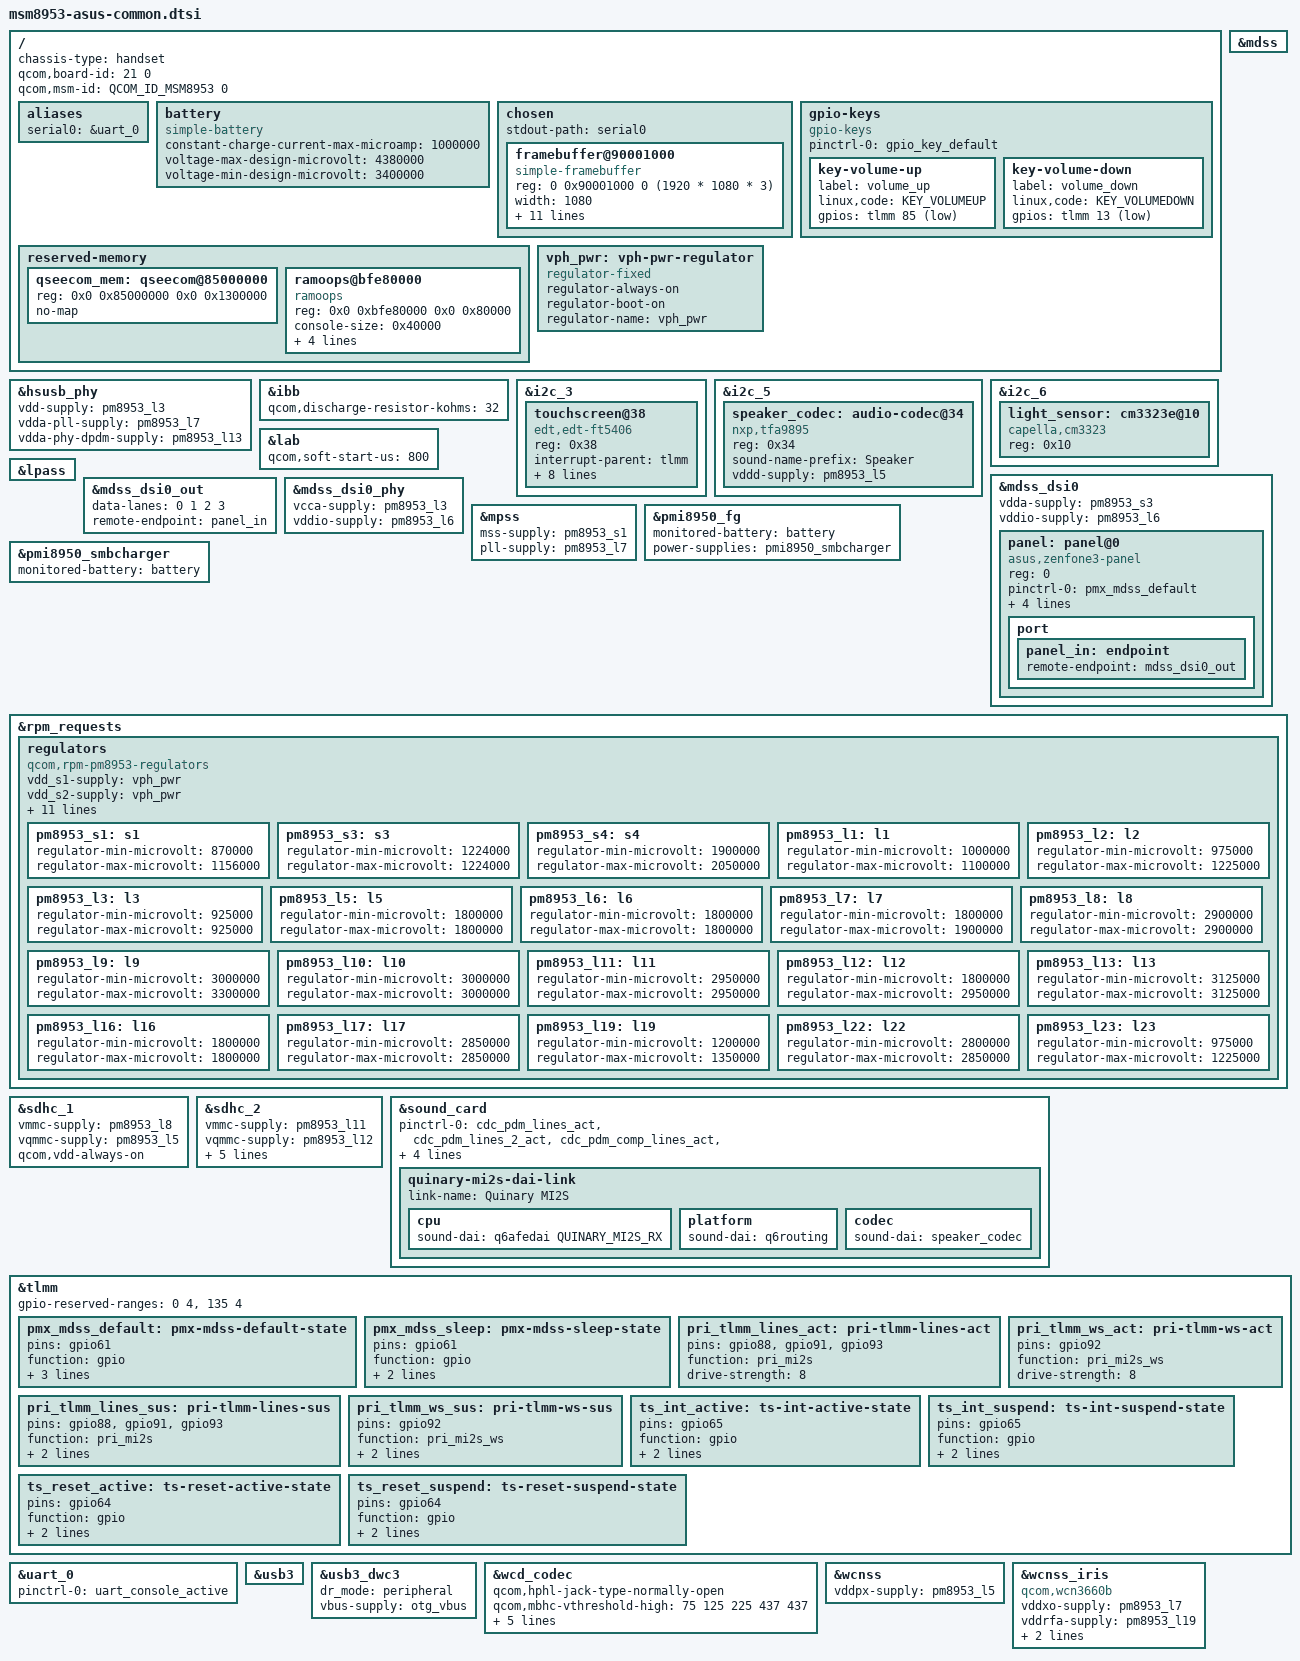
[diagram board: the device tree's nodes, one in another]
// SPDX-License-Identifier: BSD-3-Clause
/*
 * Copyright (c) 2024, Antony Kurniawan S. <postmarketos@smankusors.com>
 */
/dts-v1/;

#include <dt-bindings/arm/qcom,ids.h>
#include "msm8953.dtsi"
#include "pm8953.dtsi"
#include "pmi8950.dtsi"

/ {
	chassis-type = "handset";
	qcom,board-id = <21 0>;
	qcom,msm-id = <QCOM_ID_MSM8953 0>;

	aliases {
		serial0 = &uart_0;
	};

	battery: battery {
		compatible = "simple-battery";

		constant-charge-current-max-microamp = <1000000>;
		voltage-max-design-microvolt = <4380000>;
		voltage-min-design-microvolt = <3400000>;
	};

	chosen {
		#address-cells = <2>;
		#size-cells = <2>;
		ranges;
		stdout-path = "serial0";

		framebuffer@90001000 {
			compatible = "simple-framebuffer";
			reg = <0 0x90001000 0 (1920 * 1080 * 3)>;

			width = <1080>;
			height = <1920>;
			stride = <(1080 * 3)>;
			format = "r8g8b8";

			power-domains = <&gcc MDSS_GDSC>;

			clocks = <&gcc GCC_MDSS_AHB_CLK>,
				 <&gcc GCC_MDSS_AXI_CLK>,
				 <&gcc GCC_MDSS_VSYNC_CLK>,
				 <&gcc GCC_MDSS_MDP_CLK>,
				 <&gcc GCC_MDSS_BYTE0_CLK>,
				 <&gcc GCC_MDSS_PCLK0_CLK>,
				 <&gcc GCC_MDSS_ESC0_CLK>;
		};
	};

	gpio-keys {
		compatible = "gpio-keys";

		pinctrl-0 = <&gpio_key_default>;
		pinctrl-names = "default";

		key-volume-up {
			label = "volume_up";
			linux,code = <KEY_VOLUMEUP>;
			gpios = <&tlmm 85 GPIO_ACTIVE_LOW>;
		};

		key-volume-down {
			label = "volume_down";
			linux,code = <KEY_VOLUMEDOWN>;
			gpios = <&tlmm 13 GPIO_ACTIVE_LOW>;
		};
	};

	reserved-memory {
		/delete-node/ qseecom@85b00000;
		qseecom_mem: qseecom@85000000 {
			reg = <0x0 0x85000000 0x0 0x1300000>;
			no-map;
		};

		ramoops@bfe80000 {
			compatible = "ramoops";
			reg = <0x0 0xbfe80000 0x0 0x80000>;
			console-size = <0x40000>;
			ftrace-size = <0x0>;
			record-size = <0x2000>;
			pmsg-size = <0x0>;
			dump-size = <0x3e000>;
		};
	};

	vph_pwr: vph-pwr-regulator {
		compatible = "regulator-fixed";
		regulator-always-on;
		regulator-boot-on;
		regulator-name = "vph_pwr";
	};
};

&hsusb_phy {
	vdd-supply = <&pm8953_l3>;
	vdda-pll-supply = <&pm8953_l7>;
	vdda-phy-dpdm-supply = <&pm8953_l13>;

	status = "okay";
};

&ibb {
	qcom,discharge-resistor-kohms = <32>;
};

&i2c_3 {
	status = "okay";

	touchscreen@38 {
		compatible = "edt,edt-ft5406";
		reg = <0x38>;

		interrupt-parent = <&tlmm>;
		interrupts = <65 IRQ_TYPE_EDGE_FALLING>;

		pinctrl-0 = <&ts_reset_active &ts_int_active>;
		pinctrl-1 = <&ts_reset_suspend &ts_int_suspend>;
		pinctrl-names = "default", "sleep";

		reset-gpios = <&tlmm 64 GPIO_ACTIVE_LOW>;

		iovcc-supply = <&pm8953_l6>;
		vcc-supply = <&pm8953_l10>;

		touchscreen-size-x = <1080>;
		touchscreen-size-y = <1920>;
	};
};

&i2c_5 {
	status = "okay";

	speaker_codec: audio-codec@34 {
		compatible = "nxp,tfa9895";
		reg = <0x34>;
		sound-name-prefix = "Speaker";
		vddd-supply = <&pm8953_l5>;
		#sound-dai-cells = <0>;
	};
};

&i2c_6 {
	status = "okay";

	light_sensor: cm3323e@10 {
		compatible = "capella,cm3323";
		reg = <0x10>;
	};
};

&lab {
	qcom,soft-start-us = <800>;
};

&lpass {
	status = "okay";
};

&mdss {
	status = "okay";
};

&mdss_dsi0 {
	vdda-supply = <&pm8953_s3>;
	vddio-supply = <&pm8953_l6>;
	status = "okay";

	panel: panel@0 {
		compatible = "asus,zenfone3-panel";
		reg = <0>;

		pinctrl-0 = <&pmx_mdss_default>;
		pinctrl-1 = <&pmx_mdss_sleep>;
		pinctrl-names = "default", "sleep";

		reset-gpios = <&tlmm 61 GPIO_ACTIVE_LOW>;

		vsp-supply = <&lab>;
		vsn-supply = <&ibb>;

		port {
			panel_in: endpoint {
				remote-endpoint = <&mdss_dsi0_out>;
			};
		};
	};
};

&mdss_dsi0_out {
	data-lanes = <0 1 2 3>;
	remote-endpoint = <&panel_in>;
};

&mdss_dsi0_phy {
	vcca-supply = <&pm8953_l3>;
	vddio-supply = <&pm8953_l6>;

	status = "okay";
};

&mpss {
	mss-supply = <&pm8953_s1>;
	pll-supply = <&pm8953_l7>;

	status = "okay";
};

&pmi8950_fg {
	monitored-battery = <&battery>;
	power-supplies = <&pmi8950_smbcharger>;
};

&pmi8950_smbcharger {
	monitored-battery = <&battery>;
	status = "okay";
};

&rpm_requests {
	regulators {
		compatible = "qcom,rpm-pm8953-regulators";
		vdd_s1-supply = <&vph_pwr>;
		vdd_s2-supply = <&vph_pwr>;
		vdd_s3-supply = <&vph_pwr>;
		vdd_s4-supply = <&vph_pwr>;
		vdd_s5-supply = <&vph_pwr>;
		vdd_s6-supply = <&vph_pwr>;
		vdd_s7-supply = <&vph_pwr>;
		vdd_l1-supply = <&pm8953_s3>;
		vdd_l2_l3-supply = <&pm8953_s3>;
		vdd_l4_l5_l6_l7_l16_l19-supply = <&pm8953_s4>;
		vdd_l8_l11_l12_l13_l14_l15-supply = <&vph_pwr>;
		vdd_l9_l10_l17_l18_l22-supply = <&vph_pwr>;
		vdd_l23-supply = <&pm8953_s3>;

		pm8953_s1: s1 {
			regulator-min-microvolt = <870000>;
			regulator-max-microvolt = <1156000>;
		};

		pm8953_s3: s3 {
			regulator-min-microvolt = <1224000>;
			regulator-max-microvolt = <1224000>;
		};

		pm8953_s4: s4 {
			regulator-min-microvolt = <1900000>;
			regulator-max-microvolt = <2050000>;
		};

		pm8953_l1: l1 {
			regulator-min-microvolt = <1000000>;
			regulator-max-microvolt = <1100000>;
		};

		pm8953_l2: l2 {
			regulator-min-microvolt = <975000>;
			regulator-max-microvolt = <1225000>;
		};

		pm8953_l3: l3 {
			regulator-min-microvolt = <925000>;
			regulator-max-microvolt = <925000>;
		};

		pm8953_l5: l5 {
			regulator-min-microvolt = <1800000>;
			regulator-max-microvolt = <1800000>;
		};

		pm8953_l6: l6 {
			regulator-min-microvolt = <1800000>;
			regulator-max-microvolt = <1800000>;
		};

		pm8953_l7: l7 {
			regulator-min-microvolt = <1800000>;
			regulator-max-microvolt = <1900000>;
		};

		pm8953_l8: l8 {
			regulator-min-microvolt = <2900000>;
			regulator-max-microvolt = <2900000>;
		};

		pm8953_l9: l9 {
			regulator-min-microvolt = <3000000>;
			regulator-max-microvolt = <3300000>;
		};

		pm8953_l10: l10 {
			regulator-min-microvolt = <3000000>;
			regulator-max-microvolt = <3000000>;
		};

		pm8953_l11: l11 {
			regulator-min-microvolt = <2950000>;
			regulator-max-microvolt = <2950000>;
		};

		pm8953_l12: l12 {
			regulator-min-microvolt = <1800000>;
			regulator-max-microvolt = <2950000>;
		};

		pm8953_l13: l13 {
			regulator-min-microvolt = <3125000>;
			regulator-max-microvolt = <3125000>;
		};

		pm8953_l16: l16 {
			regulator-min-microvolt = <1800000>;
			regulator-max-microvolt = <1800000>;
		};

		pm8953_l17: l17 {
			regulator-min-microvolt = <2850000>;
			regulator-max-microvolt = <2850000>;
		};

		pm8953_l19: l19 {
			regulator-min-microvolt = <1200000>;
			regulator-max-microvolt = <1350000>;
		};

		pm8953_l22: l22 {
			regulator-min-microvolt = <2800000>;
			regulator-max-microvolt = <2850000>;
		};

		pm8953_l23: l23 {
			regulator-min-microvolt = <975000>;
			regulator-max-microvolt = <1225000>;
		};
	};
};

&sdhc_1 {
	vmmc-supply = <&pm8953_l8>;
	vqmmc-supply = <&pm8953_l5>;
	qcom,vdd-always-on;

	status = "okay";
};

&sdhc_2 {
	vmmc-supply = <&pm8953_l11>;
	vqmmc-supply = <&pm8953_l12>;

	cd-gpios = <&tlmm 133 GPIO_ACTIVE_LOW>;

	pinctrl-0 = <&sdc2_clk_on &sdc2_cmd_on &sdc2_data_on &sdc2_cd_on>;
	pinctrl-1 = <&sdc2_clk_off &sdc2_cmd_off &sdc2_data_off &sdc2_cd_off>;
	pinctrl-names = "default", "sleep";

	status = "okay";
};

&sound_card {
	status = "okay";

	pinctrl-0 = <&cdc_pdm_lines_act
		&cdc_pdm_lines_2_act
		&cdc_pdm_comp_lines_act
		&pri_tlmm_lines_act
		&pri_tlmm_ws_act>;
	pinctrl-1 = <&cdc_pdm_lines_sus
		&cdc_pdm_lines_2_sus
		&cdc_pdm_comp_lines_sus
		&pri_tlmm_lines_sus
		&pri_tlmm_ws_sus>;
	pinctrl-names = "default", "sleep";

	quinary-mi2s-dai-link {
		link-name = "Quinary MI2S";
		cpu {
			sound-dai = <&q6afedai QUINARY_MI2S_RX>;
		};

		platform {
			sound-dai = <&q6routing>;
		};

		codec {
			sound-dai = <&speaker_codec>;
		};
	};
};

&tlmm {
	gpio-reserved-ranges = <0 4>, <135 4>;

	pmx_mdss_default: pmx-mdss-default-state {
		pins = "gpio61";
		function = "gpio";
		drive-strength = <8>;
		bias-disable;
		output-high;
	};

	pmx_mdss_sleep: pmx-mdss-sleep-state {
		pins = "gpio61";
		function = "gpio";
		drive-strength = <2>;
		bias-pull-down;
	};

	pri_tlmm_lines_act: pri-tlmm-lines-act {
		pins = "gpio88", "gpio91", "gpio93";
		function = "pri_mi2s";
		drive-strength = <8>;
	};

	pri_tlmm_lines_sus: pri-tlmm-lines-sus {
		pins = "gpio88", "gpio91", "gpio93";
		function = "pri_mi2s";
		drive-strength = <2>;
		bias-pull-down;
	};

	pri_tlmm_ws_act: pri-tlmm-ws-act {
		pins = "gpio92";
		function = "pri_mi2s_ws";
		drive-strength = <8>;
	};

	pri_tlmm_ws_sus: pri-tlmm-ws-sus {
		pins = "gpio92";
		function = "pri_mi2s_ws";
		drive-strength = <2>;
		bias-pull-down;
	};

	ts_int_active: ts-int-active-state {
		pins = "gpio65";
		function = "gpio";
		drive-strength = <8>;
		bias-pull-up;
	};

	ts_int_suspend: ts-int-suspend-state {
		pins = "gpio65";
		function = "gpio";
		drive-strength = <2>;
		bias-pull-down;
	};

	ts_reset_active: ts-reset-active-state {
		pins = "gpio64";
		function = "gpio";
		drive-strength = <8>;
		bias-pull-up;
	};

	ts_reset_suspend: ts-reset-suspend-state {
		pins = "gpio64";
		function = "gpio";
		drive-strength = <2>;
		bias-pull-down;
	};
};

&uart_0 {
	pinctrl-0 = <&uart_console_active>;
	pinctrl-names = "default";

	status = "okay";
};

&usb3 {
	status = "okay";
};

&usb3_dwc3 {
	dr_mode = "peripheral";
	vbus-supply = <&otg_vbus>;
};

&wcd_codec {
	status = "okay";

	qcom,hphl-jack-type-normally-open;

	qcom,mbhc-vthreshold-high = <75 125 225 437 437>;
	qcom,mbhc-vthreshold-low = <75 125 225 437 437>;
	qcom,micbias1-ext-cap;

	vdd-cdc-io-supply = <&pm8953_l5>;
	vdd-cdc-tx-rx-cx-supply = <&pm8953_s4>;
	vdd-micbias-supply = <&pm8953_l13>;
};

&wcnss {
	status = "okay";
	vddpx-supply = <&pm8953_l5>;
};

&wcnss_iris {
	compatible = "qcom,wcn3660b";

	vddxo-supply = <&pm8953_l7>;
	vddrfa-supply = <&pm8953_l19>;
	vddpa-supply = <&pm8953_l9>;
	vdddig-supply = <&pm8953_l5>;
};
